# RL6845_IP_SVD register map
Vendor: Realtek
Registers are 32-bit, read-write, reset 0x0 unless marked. A register's access mark holds for its fields unless they carry their own. Offsets are from the block's base; [hi:lo] are bit positions; {n}, {i} and the like mark numbered series; <NAME> marks a mode.

## PKE
Base 0x00000000
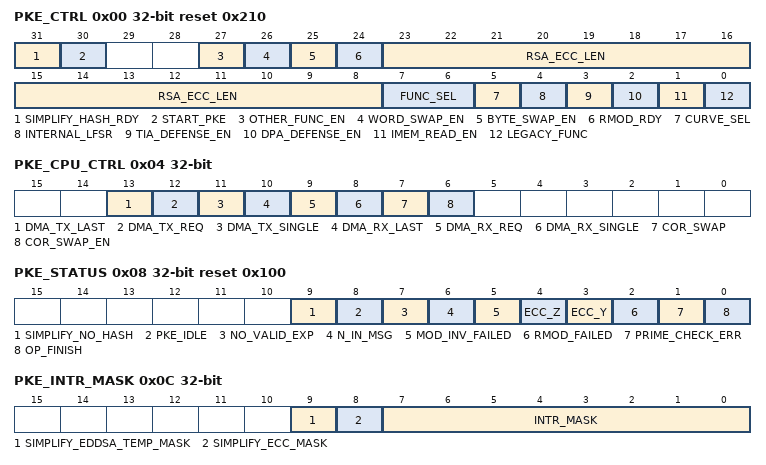
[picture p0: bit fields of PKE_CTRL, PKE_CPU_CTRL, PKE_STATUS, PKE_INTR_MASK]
0x00 PKE_CTRL access per field reset 0x210 — Public Key Engine Control Register
  [31] SIMPLIFY_HASH_RDY rw — 1: SIMPLIFY_ECDSA/EdDSA hash value ready
  [30] START_PKE wo — W1: write 1 to start PKE (cleared automatically by PKE)
  [27] OTHER_FUNC_EN rw — Other functions (not RSA/ECC) enable bit 1: enabled 0: disabled (RSA: mudolar exponentiation/ECC: scalar multiplication)
  [26] WORD_SWAP_EN rw — Endian word swap enable (only support in MMEM)
  [25] BYTE_SWAP_EN rw — Endian byte swap enable (only support in MMEM)
  [24] RMOD_RDY rw — R^2 mod N ready 1: not need to calculate the R^2 mod N, already stored by user For RSA, R^2 mod N ready and DPA defense can't be enabled at the same time.
  [23:8] RSA_ECC_LEN rw — Precise RSA/ECC length in bits Caution: When performing ECC point operation under binary field, there are situation which width of module larger than ECC length. For example, width of f(x) of sect163r2 is 164, larger then ECC length 163. In this situation, just fill in precise ECC length 163.
  [7:6] FUNC_SEL rw — 2'b00: ECC Prime field 2'b01: ECC Binary field 2'b10: RSA 2'b11: Edwards or Montgomery Curves
  [5] CURVE_SEL rw — 1'b0: Edwards Curves 1'b1: Montgomery Curves
  [4] INTERNAL_LFSR rw — 1: Use internal LFSR 0: Do not use internal LFSR If not use internal LFSR, user needs to initial a 32-bit random number (can't be 0) to MMEM address 0x0001_0180 before starting the PKE for ECC/RSA PDA defense. And if configured to ECC/Edwards, please also clear the upper address 0x0001_0184 ~ 0x0001_01BF (for 3072 config) or 0x0001_0184 ~ 0x0001_01CF (for 4096 config) to 0.
  [3] TIA_DEFENSE_EN rw — 1: Timing attack defense enable 0: Timing attack defense disable
  [2] DPA_DEFENSE_EN rw — 1: DPA defense enable 0: DPA defense disable
  [1] IMEM_READ_EN rw — 1: Enable IMEM read (or else, the IMEM can only be read when bit[30]=1) 0: IMEM can't be read
  [0] LEGACY_FUNC rw — Go to end loop after the current function call (legacy function)
0x04 PKE_CPU_CTRL ro — Public Key Engine CPU Control Register
  [13] DMA_TX_LAST
  [12] DMA_TX_REQ — DMA Tx request
  [11] DMA_TX_SINGLE
  [10] DMA_RX_LAST
  [9] DMA_RX_REQ — DMA Rx request
  [8] DMA_RX_SINGLE
  [7] COR_SWAP — Coordinate swap or not
  [6] COR_SWAP_EN — Coordinate swap enable
0x08 PKE_STATUS reset 0x100 — Public Key Engine Status Register
  [9] SIMPLIFY_NO_HASH — SIMPLIFY_ECDSA/EdDSA need hash value
  [8] PKE_IDLE
  [7] NO_VALID_EXP — No valid exponent
  [6] N_IN_MSG — N < input message for RSA
  [5] MOD_INV_FAILED — Module inverse failed
  [4] ECC_Z — ECC Z = 0
  [3] ECC_Y — ECC odd point (Y = 0) (Montgomery curve will not check the Y value)
  [2] RMOD_FAILED — R^2 mod N failed
  [1] PRIME_CHECK_ERR — Prime check error (for modular number)
  [0] OP_FINISH — ECC/RSA operation finish
0x0C PKE_INTR_MASK — Public Key Engine Interrupt Mask Register
  [9] SIMPLIFY_EDDSA_TEMP_MASK — Wait for SIMPLIFY_EdDSA temp_2 hash value 0: interrupt masked 1: interrupt not masked
  [8] SIMPLIFY_ECC_MASK — Wait for SIMPLIFY_ECDSA hash value or wait for SIMPLIFY_EdDSA hash value (temp & private_hash) 0: interrupt masked 1: interrupt not masked
  [7:0] INTR_MASK — Interrupt mask for each interrupt in status register 0: interrupt masked 1: interrupt not masked
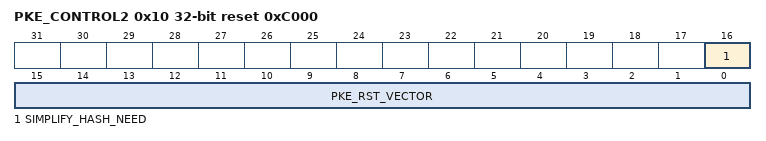
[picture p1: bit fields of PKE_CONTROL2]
0x10 PKE_CONTROL2 reset 0xC000 — Public Key Engine Control Register 2
  [16] SIMPLIFY_HASH_NEED — SIMPLIFY_ECDSA/EdDSA need hash value
  [15:0] PKE_RST_VECTOR — PKE reset vector = {Control Register 2 value, 2'b00}
0x14 PKE_SWAP_BAR — Public Key Engine Swap Base Address Register
  [11:5] SWAP_BAR — Word swap base address in word (32 bits)
0x1C PKE_VER_NUM ro — Public Key Engine Version Number Register
  [31:0] VER_NUM — 32-bit code update data or verison number, such as 32'h20211015
